AUTOSAR XML (schema 4-2-2)
package /Acme/Interfaces
  client server interface IMixedArgs
    operation Get
      arg value: type=TWithin, direction=OUT
    operation Set
      arg value: type=TWithin, direction=IN
package /Acme/Components
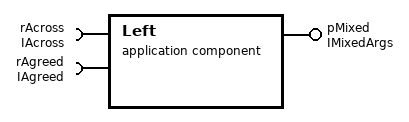
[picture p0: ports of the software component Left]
  application sw component type Left
    require port rAcross: required-interface=IAcross
    require port rAgreed: required-interface=IAgreed
    provide port pMixed: provided-interface=IMixedArgs
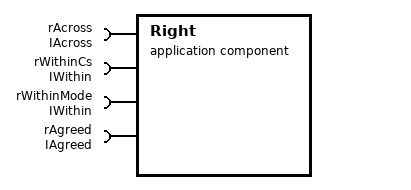
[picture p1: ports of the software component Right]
  application sw component type Right
    4 x require port:
      rAcross: required-interface=IAcross
      rWithinCs: required-interface=IWithin
      rWithinMode: required-interface=IWithin
      rAgreed: required-interface=IAgreed
package /Acme/Elsewhere
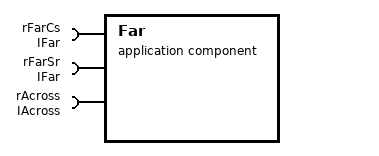
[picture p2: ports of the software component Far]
  application sw component type Far
    require port rFarCs: required-interface=IFar
    require port rFarSr: required-interface=IFar
    require port rAcross: required-interface=IAcross
